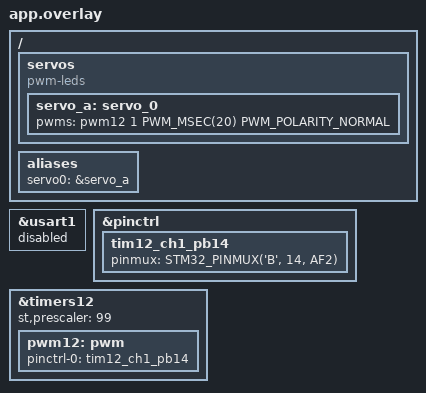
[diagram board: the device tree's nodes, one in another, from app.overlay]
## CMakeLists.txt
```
cmake_minimum_required(VERSION 3.20.0)
find_package(Zephyr REQUIRED HINTS $ENV{ZEPHYR_BASE})
project(example)
set(DRIVER_DIR /home/dmi/zephyr-boards/stm32h573ri/firmware/tests/EmbeddedCourse_FPT_DMI/driver)
target_sources(app PRIVATE src/main.c)
target_include_directories(app PRIVATE
  ${DRIVER_DIR}/peripherals/pwm
  ${DRIVER_DIR}/devices/servo
)
target_sources(app PRIVATE
  ${DRIVER_DIR}/peripherals/pwm/driver_pwm.c
  ${DRIVER_DIR}/devices/servo/driver_servo.c
)
```

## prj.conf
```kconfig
CONFIG_PRINTK=y
CONFIG_CONSOLE=y
CONFIG_USE_SEGGER_RTT=y
CONFIG_RTT_CONSOLE=y
CONFIG_UART_CONSOLE=n
CONFIG_PWM=y
CONFIG_BOOTLOADER_MCUBOOT=y
CONFIG_STM32_ENABLE_DEBUG_SLEEP_STOP=y
```

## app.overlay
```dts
/ {
	servos {
		compatible = "pwm-leds";
		servo_a: servo_0 {
			pwms = <&pwm12 1 PWM_MSEC(20) PWM_POLARITY_NORMAL>;   /* TIM12 kênh 1, 20 ms */
		};
	};
	aliases {
		servo0 = &servo_a;
	};
};

&usart1 { status = "disabled"; };   /* PB14/PB15 là USART1 trong board DTS */

&pinctrl {
	tim12_ch1_pb14: tim12_ch1_pb14 {
		pinmux = <STM32_PINMUX('B', 14, AF2)>;
	};
};

&timers12 {
	st,prescaler = <99>;    /* 250 MHz / 100 = 2.5 MHz → 20 ms = 50000 tick (< 65536), bước 0.4 µs */
	status = "okay";
	pwm12: pwm {
		pinctrl-0 = <&tim12_ch1_pb14>;
		pinctrl-names = "default";
		status = "okay";
	};
};
```

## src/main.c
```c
/* Servo: continuous angle adjustment. Alternates a 1-degree step sweep (set_angle every 20 ms)
 * and a driver_servo_sweep() ramp, forever. Prints the angle about twice per second.
 */
#include <zephyr/kernel.h>
#include <zephyr/sys/printk.h>

#include "driver_servo.h"

int main(void)
{
	const struct driver_servo_cfg cfg = {
		.min_pulse_us = 500, .max_pulse_us = 2400, .max_angle = 180,
	};
	int ret = driver_servo_init(0, &cfg);

	printk("servo init=%d\n", ret);
	for (int round = 0;; round++) {
		printk("round %d: 1-degree steps 0 -> 180 -> 0 (20 ms/step)\n", round);
		for (int a = 0; a <= 180; a++) {
			driver_servo_set_angle(0, a);
			if (a % 30 == 0) {
				printk("  angle %d\n", a);
			}
			k_msleep(20);
		}
		for (int a = 180; a >= 0; a--) {
			driver_servo_set_angle(0, a);
			if (a % 30 == 0) {
				printk("  angle %d\n", a);
			}
			k_msleep(20);
		}
		printk("round %d: ramp 0 -> 180 -> 0 in 2 s each\n", round);
		ret = driver_servo_sweep(0, 0, 180, 2000);
		ret |= driver_servo_sweep(0, 180, 0, 2000);
		printk("  sweep ret=%d\n", ret);
	}
	return 0;
}
```
